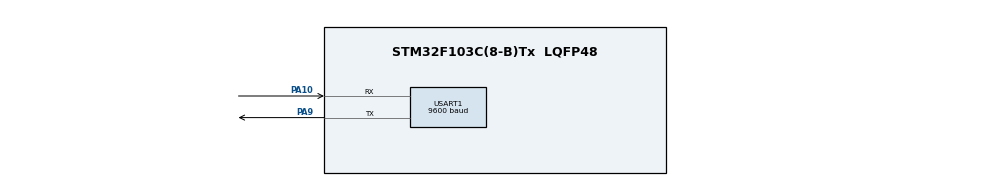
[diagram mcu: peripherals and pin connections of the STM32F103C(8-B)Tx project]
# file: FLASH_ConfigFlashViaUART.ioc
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Mcu.Family=STM32F1
Mcu.Name=STM32F103C(8-B)Tx
Mcu.Package=LQFP48
NVIC.PriorityGroup=NVIC_PRIORITYGROUP_4
NVIC.USART1_IRQn=true\:0\:0\:false\:false\:true\:true\:true
PA10.Mode=Asynchronous
PA10.Signal=USART1_RX
PA13.Mode=Serial_Wire
PA13.Signal=SYS_JTMS-SWDIO
PA14.Mode=Serial_Wire
PA14.Signal=SYS_JTCK-SWCLK
PA9.Mode=Asynchronous
PA9.Signal=USART1_TX
ProjectManager.HeapSize=0x200
ProjectManager.StackSize=0x400
ProjectManager.TargetToolchain=MDK-ARM V5
RCC.APB1Freq_Value=8000000
RCC.APB2Freq_Value=8000000
USART1.BaudRate=9600
USART1.VirtualMode=VM_ASYNC
board=custom

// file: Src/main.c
/* USER CODE BEGIN Header */
/**
  ******************************************************************************
  * @file           : main.c
  * @brief          : Main program body
  ******************************************************************************
  * @attention
  *
  * <h2><center>&copy; Copyright (c) 2019 STMicroelectronics.
  * All rights reserved.</center></h2>
  *
  * This software component is licensed by ST under BSD 3-Clause license,
  * the "License"; You may not use this file except in compliance with the
  * License. You may obtain a copy of the License at:
  *                        opensource.org/licenses/BSD-3-Clause
  *
  ******************************************************************************
  */
	/* --COPYRIGHT--,
	 * Copyright (c) 2019, TAPIT Co., Ltd.
	 * https://tapit.vn
	 * *********************** FLASH_ConfigFlashViaUART **************************
	 *  Description: Change the value in memory via UART 1. The transmitted data
			must have the end character “|” to indicate the process of receiving data
			has ended.
	 *  Version:    1.0
	 *  Author:     Hang Tran
	 *  Release:    May 27, 2019
	 *  Built with CubeMX Version 5.2.0 and Keil C Version 5.26.2
	 ******************************************************************************
	 */

/* USER CODE END Header */

#include "main.h"

/* USER CODE BEGIN Includes */
#include "stdbool.h"
#include "flash.h"
/* USER CODE END Includes */

/* USER CODE BEGIN PD */
#define DATA_START_ADDRESS 		 	((uint32_t)0x0801FC00)	//Page 127
#define LENGTH_START_ADDRESS 		((uint32_t)0x0801F810)	//Page 126

/* USER CODE END PD */

UART_HandleTypeDef huart1;

/* USER CODE BEGIN PV */
char Rxdata[2] = {0};
char UARTbuff[50] = {0};
char data[50] = {0};
uint8_t UARTlen = 0;
bool isReceiveCplt = false;

/* USER CODE END PV */

void SystemClock_Config(void);
static void MX_GPIO_Init(void);
static void MX_USART1_UART_Init(void);

/* USER CODE BEGIN 0 */
void HAL_UART_RxCpltCallback(UART_HandleTypeDef *huart)
{
	if(huart->Instance == USART1)
	{
		if(Rxdata[0] != '|') UARTbuff[UARTlen++] = Rxdata[0];
		else isReceiveCplt = true;
	}
	HAL_UART_Receive_IT(&huart1, (uint8_t *)Rxdata, 1);
}

/* USER CODE END 0 */

int main(void)
{

  /* MCU Configuration--------------------------------------------------------*/

  /* Reset of all peripherals, Initializes the Flash interface and the Systick. */
  HAL_Init();

  /* Configure the system clock */
  SystemClock_Config();

  /* Initialize all configured peripherals */
  MX_GPIO_Init();
  MX_USART1_UART_Init();
  /* USER CODE BEGIN 2 */
	HAL_UART_Receive_IT(&huart1, (uint8_t *)Rxdata, 1);

  /* USER CODE END 2 */

  /* Infinite loop */
  while (1)
  {

    /* USER CODE BEGIN 3 */
		if(isReceiveCplt == true)
		{
			Flash_ProgramPage(UARTbuff, DATA_START_ADDRESS, LENGTH_START_ADDRESS);
			HAL_Delay(100);
			Flash_ReadChar(data, DATA_START_ADDRESS, LENGTH_START_ADDRESS);
			printf("Read from Flash: %s\r\n",data);
			deleteBuffer(UARTbuff);
			UARTlen = 0;
			isReceiveCplt = false;
		}
  }
  /* USER CODE END 3 */
}

void SystemClock_Config(void)
{
  RCC_OscInitTypeDef RCC_OscInitStruct = {0};
  RCC_ClkInitTypeDef RCC_ClkInitStruct = {0};

  /** Initializes the CPU, AHB and APB busses clocks
  */
  RCC_OscInitStruct.OscillatorType = RCC_OSCILLATORTYPE_HSI;
  RCC_OscInitStruct.HSIState = RCC_HSI_ON;
  RCC_OscInitStruct.HSICalibrationValue = RCC_HSICALIBRATION_DEFAULT;
  RCC_OscInitStruct.PLL.PLLState = RCC_PLL_NONE;
  if (HAL_RCC_OscConfig(&RCC_OscInitStruct) != HAL_OK)
  {
    Error_Handler();
  }
  /** Initializes the CPU, AHB and APB busses clocks
  */
  RCC_ClkInitStruct.ClockType = RCC_CLOCKTYPE_HCLK|RCC_CLOCKTYPE_SYSCLK
                              |RCC_CLOCKTYPE_PCLK1|RCC_CLOCKTYPE_PCLK2;
  RCC_ClkInitStruct.SYSCLKSource = RCC_SYSCLKSOURCE_HSI;
  RCC_ClkInitStruct.AHBCLKDivider = RCC_SYSCLK_DIV1;
  RCC_ClkInitStruct.APB1CLKDivider = RCC_HCLK_DIV1;
  RCC_ClkInitStruct.APB2CLKDivider = RCC_HCLK_DIV1;

  if (HAL_RCC_ClockConfig(&RCC_ClkInitStruct, FLASH_LATENCY_0) != HAL_OK)
  {
    Error_Handler();
  }
}

static void MX_USART1_UART_Init(void)
{

  huart1.Instance = USART1;
  huart1.Init.BaudRate = 9600;
  huart1.Init.WordLength = UART_WORDLENGTH_8B;
  huart1.Init.StopBits = UART_STOPBITS_1;
  huart1.Init.Parity = UART_PARITY_NONE;
  huart1.Init.Mode = UART_MODE_TX_RX;
  huart1.Init.HwFlowCtl = UART_HWCONTROL_NONE;
  huart1.Init.OverSampling = UART_OVERSAMPLING_16;
  if (HAL_UART_Init(&huart1) != HAL_OK)
  {
    Error_Handler();
  }

}

static void MX_GPIO_Init(void)
{

  /* GPIO Ports Clock Enable */
  __HAL_RCC_GPIOA_CLK_ENABLE();

}

/* USER CODE BEGIN 4 */
#ifdef __GNUC__
  #define PUTCHAR_PROTOTYPE int __io_putchar(int ch)
#else
  #define PUTCHAR_PROTOTYPE int fputc(int ch, FILE *f)
#endif /* __GNUC__ */
PUTCHAR_PROTOTYPE
{
    HAL_UART_Transmit(&huart1, (uint8_t *)&ch, 1, 100);
    return ch;
}

/* USER CODE END 4 */

void Error_Handler(void)
{
}

/************************ (C) COPYRIGHT STMicroelectronics *****END OF FILE****/
